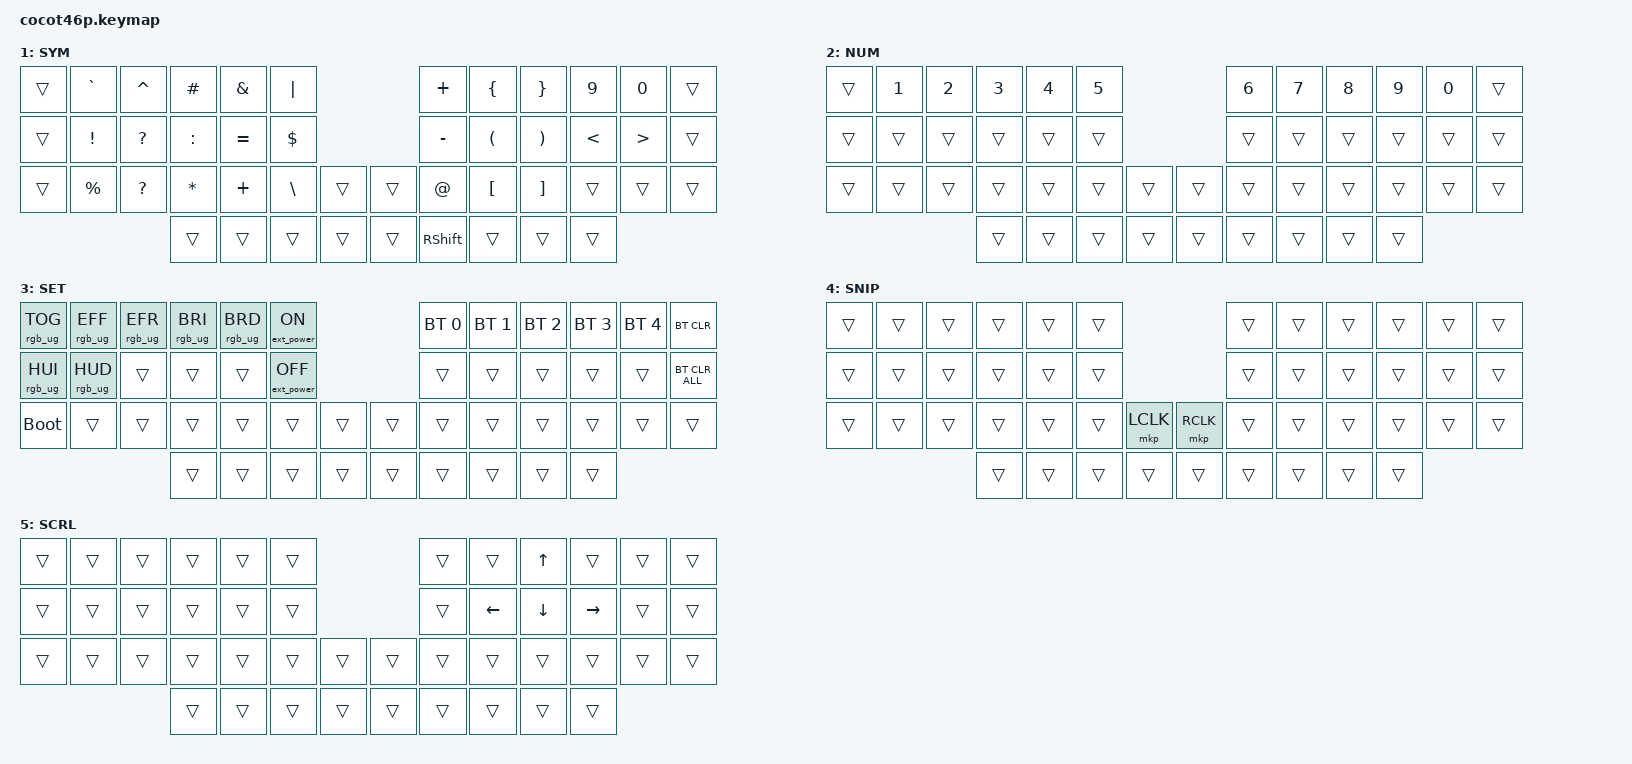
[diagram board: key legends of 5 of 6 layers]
/*
 * Copyright (c) 2021 The ZMK Contributors
 *
 * SPDX-License-Identifier: MIT
 */

#include <behaviors/mouse_keys.dtsi>
#include <dt-bindings/zmk/mouse.h>
#include <behaviors.dtsi>
#include <dt-bindings/zmk/bt.h>
#include <dt-bindings/zmk/ext_power.h>
#include <dt-bindings/zmk/keys.h>

#include <dt-bindings/zmk/rgb.h>

/ {
    combos { compatible = "zmk,combos"; };

    behaviors {
        hm: homerow_mods {
            compatible = "zmk,behavior-hold-tap";
            label = "HOMEROW_MODS";
            bindings = <&kp>, <&kp>;

            #binding-cells = <2>;
            tapping-term-ms = <200>;
            quick-tap-ms = <150>;
            flavor = "tap-preferred";
        };

        ltq: ltq {
            compatible = "zmk,behavior-hold-tap";
            label = "LTQ";
            bindings = <&mo>, <&kp>;

            #binding-cells = <2>;
            tapping-term-ms = <200>;
            quick-tap-ms = <180>;
        };

        as: auto_shift {
            compatible = "zmk,behavior-hold-tap";
            label = "AUTO_SHIFT";
            bindings = <&kp>, <&kp>;

            #binding-cells = <2>;
            tapping-term-ms = <135>;
            quick-tap-ms = <0>;
        };
    };

    keymap {
        compatible = "zmk,keymap";

        BASE {
            bindings = <
&kp TAB         &kp Q        &kp W       &kp E       &kp R         &kp T                              &kp Y        &kp U         &kp I        &kp O       &kp P                &kp BSPC
&kp CAPS        &hm LCTRL A  &hm LALT S  &hm LGUI D  &hm LSHFT F   &kp G                              &kp H        &hm RSHFT J   &hm RGUI K   &hm RALT L  &hm RCTRL SEMICOLON  &kp SQT
&kp LEFT_SHIFT  &kp Z        &kp X       &kp C       &kp V         &kp B        &mkp LCLK  &mkp RCLK  &kp N        &kp M         &kp COMMA    &kp PERIOD  &kp SLASH            &kp MINUS
                                         &kp LCTRL   &mo 1         &lt 2 SPACE  &mo 5      &mo 4      &lt 1 ENTER  &lt 5 ESC     &mo 3       
            >;

            sensor-bindings = <&inc_dec_kp C_VOLUME_UP C_VOLUME_DOWN>;
            label = "BASE";
        };

        SYM {
            bindings = <
&trans  &kp GRAVE     &kp CARET     &kp POUND     &kp AMPS      &kp PIPE                 &kp PLUS      &kp LBRC   &kp RBRC   &kp N9  &kp N0   &trans
&trans  &kp EXCL      &kp QMARK     &kp COLON     &kp EQUAL     &kp DLLR                 &kp MINUS     &kp LPAR   &kp RPAR   &kp LT  &kp GT   &trans
&trans  &kp PRCNT     &kp QMARK     &kp STAR      &kp PLUS      &kp BSLH &trans  &trans  &kp AT        &kp LBKT   &kp RBKT   &trans  &trans   &trans
                                    &trans        &trans        &trans   &trans  &trans  &kp RSHFT     &trans     &trans     &trans
            >;

            label = "SYM";
        };

        NUM {
            bindings = <
&trans  &kp N1  &kp N2  &kp N3  &kp N4  &kp N5                  &kp N6  &kp N7  &kp N8  &kp N9  &kp N0  &trans 
&trans  &trans  &trans  &trans  &trans  &trans                  &trans  &trans  &trans  &trans  &trans  &trans
&trans  &trans  &trans  &trans  &trans  &trans  &trans  &trans  &trans  &trans  &trans  &trans  &trans  &trans
                        &trans  &trans  &trans  &trans  &trans  &trans  &trans  &trans  &trans
            >;

            label = "NUM";
        };

        SET {
            bindings = <
&rgb_ug RGB_TOG  &rgb_ug RGB_EFF  &rgb_ug RGB_EFR  &rgb_ug RGB_BRI  &rgb_ug RGB_BRD  &ext_power EP_ON                   &bt BT_SEL 0  &bt BT_SEL 1  &bt BT_SEL 2  &bt BT_SEL 3  &bt BT_SEL 4  &bt BT_CLR
&rgb_ug RGB_HUI  &rgb_ug RGB_HUD  &trans           &trans           &trans           &ext_power EP_OFF                  &trans        &trans        &trans        &trans        &trans        &bt BT_CLR_ALL
&bootloader      &trans           &trans           &trans           &trans           &trans             &trans  &trans  &trans        &trans        &trans        &trans        &trans        &trans
                                                   &trans           &trans           &trans             &trans  &trans  &trans        &trans        &trans        &trans
            >;

            label = "SET";
        };

        SNIP {
            bindings = <
&trans  &trans  &trans  &trans  &trans  &trans                        &trans  &trans  &trans  &trans  &trans  &trans
&trans  &trans  &trans  &trans  &trans  &trans                        &trans  &trans  &trans  &trans  &trans  &trans
&trans  &trans  &trans  &trans  &trans  &trans  &mkp LCLK  &mkp RCLK  &trans  &trans  &trans  &trans  &trans  &trans
                        &trans  &trans  &trans  &trans     &trans     &trans  &trans  &trans  &trans
            >;

            label = "SNIP";
        };

        SCRL {
            bindings = <
&trans  &trans  &trans  &trans  &trans  &trans                  &trans  &trans    &kp UP    &trans     &trans  &trans 
&trans  &trans  &trans  &trans  &trans  &trans                  &trans  &kp LEFT  &kp DOWN  &kp RIGHT  &trans  &trans
&trans  &trans  &trans  &trans  &trans  &trans  &trans  &trans  &trans  &trans    &trans    &trans     &trans  &trans
                        &trans  &trans  &trans  &trans  &trans  &trans  &trans    &trans    &trans  
            >;

            label = "SCRL";
        };
    };
};
